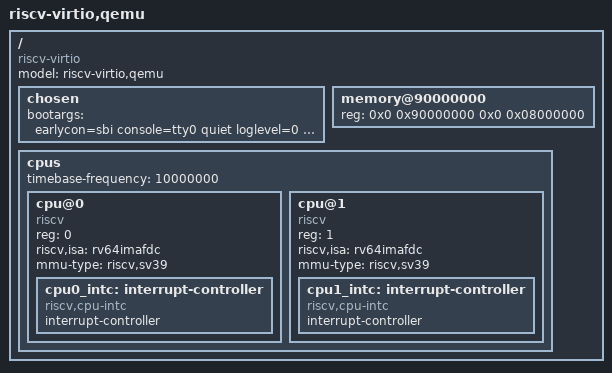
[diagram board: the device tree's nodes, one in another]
/*
 * Device tree for Guest Partition Linux (RISC-V 64 hw-virt).
 * 128MB RAM at IPA 0x90000000, 2 vCPUs with SBI HSM SMP boot.
 * No UART - uses virtio-console via shared memory.
 */

/dts-v1/;

/ {
	compatible = "riscv-virtio";
	model = "riscv-virtio,qemu";
	#address-cells = <2>;
	#size-cells = <2>;

	chosen {
		bootargs = "earlycon=sbi console=tty0 quiet loglevel=0 nokaslr";
	};

	memory@90000000 {
		device_type = "memory";
		reg = <0x0 0x90000000 0x0 0x08000000>;  /* 128MB */
	};

	cpus {
		#address-cells = <1>;
		#size-cells = <0>;
		timebase-frequency = <10000000>;

		cpu@0 {
			device_type = "cpu";
			compatible = "riscv";
			reg = <0>;
			riscv,isa = "rv64imafdc";
			mmu-type = "riscv,sv39";
			status = "okay";
			cpu0_intc: interrupt-controller {
				#interrupt-cells = <1>;
				compatible = "riscv,cpu-intc";
				interrupt-controller;
			};
		};

		cpu@1 {
			device_type = "cpu";
			compatible = "riscv";
			reg = <1>;
			riscv,isa = "rv64imafdc";
			mmu-type = "riscv,sv39";
			status = "okay";
			cpu1_intc: interrupt-controller {
				#interrupt-cells = <1>;
				compatible = "riscv,cpu-intc";
				interrupt-controller;
			};
		};
	};
};
